AUTOSAR XML (schema 4-0-3)
package /PATAC/MSM/ComponentTypes
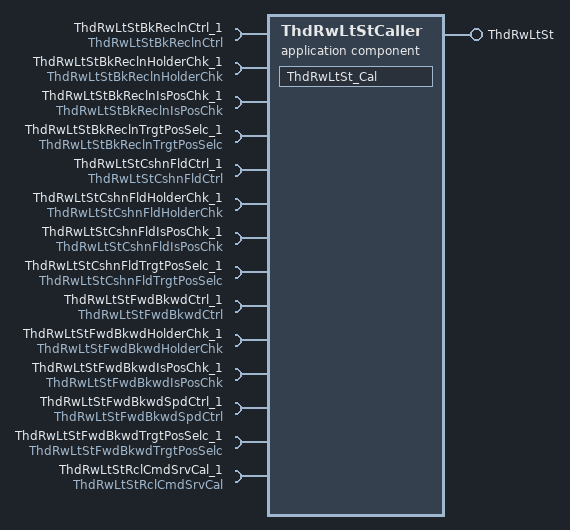
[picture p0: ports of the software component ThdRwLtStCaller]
  application sw component type ThdRwLtStCaller
    provide port ThdRwLtSt: server-com-spec{operation=ThdRwLtSt/Cal, queue-length=1}, provided-interface=ThdRwLtSt
    14 x require port:
      ThdRwLtStBkReclnCtrl_1: client-com-spec=ThdRwLtStBkReclnCtrl/Cal, required-interface=ThdRwLtStBkReclnCtrl
      ThdRwLtStBkReclnHolderChk_1: client-com-spec=ThdRwLtStBkReclnHolderChk/Cal, required-interface=ThdRwLtStBkReclnHolderChk
      ThdRwLtStBkReclnIsPosChk_1: client-com-spec=ThdRwLtStBkReclnIsPosChk/Cal, required-interface=ThdRwLtStBkReclnIsPosChk
      ThdRwLtStBkReclnTrgtPosSelc_1: client-com-spec=ThdRwLtStBkReclnTrgtPosSelc/Cal, required-interface=ThdRwLtStBkReclnTrgtPosSelc
      ThdRwLtStCshnFldCtrl_1: client-com-spec=ThdRwLtStCshnFldCtrl/Cal, required-interface=ThdRwLtStCshnFldCtrl
      ThdRwLtStCshnFldHolderChk_1: client-com-spec=ThdRwLtStCshnFldHolderChk/Cal, required-interface=ThdRwLtStCshnFldHolderChk
      ThdRwLtStCshnFldIsPosChk_1: client-com-spec=ThdRwLtStCshnFldIsPosChk/Cal, required-interface=ThdRwLtStCshnFldIsPosChk
      ThdRwLtStCshnFldTrgtPosSelc_1: client-com-spec=ThdRwLtStCshnFldTrgtPosSelc/Cal, required-interface=ThdRwLtStCshnFldTrgtPosSelc
      ThdRwLtStFwdBkwdCtrl_1: client-com-spec=ThdRwLtStFwdBkwdCtrl/Cal, required-interface=ThdRwLtStFwdBkwdCtrl
      ThdRwLtStFwdBkwdHolderChk_1: client-com-spec=ThdRwLtStFwdBkwdHolderChk/Cal, required-interface=ThdRwLtStFwdBkwdHolderChk
      ThdRwLtStFwdBkwdIsPosChk_1: client-com-spec=ThdRwLtStFwdBkwdIsPosChk/Cal, required-interface=ThdRwLtStFwdBkwdIsPosChk
      ThdRwLtStFwdBkwdSpdCtrl_1: client-com-spec=ThdRwLtStFwdBkwdSpdCtrl/Cal, required-interface=ThdRwLtStFwdBkwdSpdCtrl
      ThdRwLtStFwdBkwdTrgtPosSelc_1: client-com-spec=ThdRwLtStFwdBkwdTrgtPosSelc/Cal, required-interface=ThdRwLtStFwdBkwdTrgtPosSelc
      ThdRwLtStRclCmdSrvCal_1: client-com-spec=ThdRwLtStRclCmdSrvCal/Cal, required-interface=ThdRwLtStRclCmdSrvCal
    behavior ThdRwLtStCaller_InternalBehavior
      operation invoked event OIT_ThdRwLtSt_Cal_ThdRwLtSt_Cal: start-on-event=ThdRwLtSt_Cal, operation=ThdRwLtSt.Cal
      runnable ThdRwLtSt_Cal
        14 x sync call, all with timeout=0:
          SC_ThdRwLtStBkReclnCtrl_1_Cal: operation=ThdRwLtStBkReclnCtrl_1.Cal
          SC_ThdRwLtStBkReclnHolderChk_1_Cal: operation=ThdRwLtStBkReclnHolderChk_1.Cal
          SC_ThdRwLtStBkReclnIsPosChk_1_Cal: operation=ThdRwLtStBkReclnIsPosChk_1.Cal
          SC_ThdRwLtStCshnFldCtrl_1_Cal: operation=ThdRwLtStCshnFldCtrl_1.Cal
          SC_ThdRwLtStCshnFldHolderChk_1_Cal: operation=ThdRwLtStCshnFldHolderChk_1.Cal
          SC_ThdRwLtStCshnFldIsPosChk_1_Cal: operation=ThdRwLtStCshnFldIsPosChk_1.Cal
          SC_ThdRwLtStFwdBkwdCtrl_1_Cal: operation=ThdRwLtStFwdBkwdCtrl_1.Cal
          SC_ThdRwLtStFwdBkwdHolderChk_1_Cal: operation=ThdRwLtStFwdBkwdHolderChk_1.Cal
          SC_ThdRwLtStFwdBkwdIsPosChk_1_Cal: operation=ThdRwLtStFwdBkwdIsPosChk_1.Cal
          SC_ThdRwLtStFwdBkwdSpdCtrl_1_Cal: operation=ThdRwLtStFwdBkwdSpdCtrl_1.Cal
          SC_ThdRwLtStRclCmdSrvCal_1_Cal: operation=ThdRwLtStRclCmdSrvCal_1.Cal
          SC_ThrdRwLtStBkReclnTrgtPosSelc_1_Cal: operation=ThdRwLtStBkReclnTrgtPosSelc_1.Cal
          SC_ThrdRwLtStCshnFldTrgtPosSelc_1_Cal: operation=ThdRwLtStCshnFldTrgtPosSelc_1.Cal
          SC_ThrdRwLtStFwdBkwdTrgtPosSelc_1_Cal: operation=ThdRwLtStFwdBkwdTrgtPosSelc_1.Cal
  swc implementation ThdRwLtStCaller_Implementation: behavior=ThdRwLtStCaller_InternalBehavior
    code-descriptors:
      code Default: artifact-descriptors=autosar-engineering-object={short-label=Default, category=SWSRC}
package /PATAC/MSM/ModeAdjust/PortInterface
  15 x client server interface:
    ThdRwLtSt
      operation Cal
    ThdRwLtStBkReclnCtrl
      operation Cal
    ThdRwLtStBkReclnHolderChk
      operation Cal
    ThdRwLtStBkReclnIsPosChk
      operation Cal
    ThdRwLtStBkReclnTrgtPosSelc
      operation Cal
    ThdRwLtStCshnFldCtrl
      operation Cal
    ThdRwLtStCshnFldHolderChk
      operation Cal
    ThdRwLtStCshnFldIsPosChk
      operation Cal
    ThdRwLtStCshnFldTrgtPosSelc
      operation Cal
    ThdRwLtStFwdBkwdCtrl
      operation Cal
    ThdRwLtStFwdBkwdHolderChk
      operation Cal
    ThdRwLtStFwdBkwdIsPosChk
      operation Cal
    ThdRwLtStFwdBkwdSpdCtrl
      operation Cal
    ThdRwLtStFwdBkwdTrgtPosSelc
      operation Cal
    ThdRwLtStRclCmdSrvCal
      operation Cal
